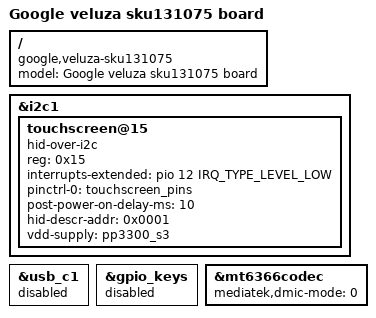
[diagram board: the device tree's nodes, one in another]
// SPDX-License-Identifier: (GPL-2.0 OR MIT)
/*
 * Copyright 2024 Google LLC
 */

/dts-v1/;
#include "mt8186-corsola-veluza.dtsi"

/ {
	model = "Google veluza sku131075 board";
	compatible = "google,veluza-sku131075", "google,veluza",
		     "google,corsola", "mediatek,mt8186";
};

&i2c1 {
	/delete-node/ touchscreen@10;
	touchscreen@15 {
		compatible = "hid-over-i2c";
		reg = <0x15>;
		interrupts-extended = <&pio 12 IRQ_TYPE_LEVEL_LOW>;
		pinctrl-names = "default";
		pinctrl-0 = <&touchscreen_pins>;
		post-power-on-delay-ms = <10>;
		hid-descr-addr = <0x0001>;
		vdd-supply = <&pp3300_s3>;
		status = "okay";
	};
};

&usb_c1 {
	status = "disabled";
};

&gpio_keys {
	status = "disabled";
};

&mt6366codec {
	mediatek,dmic-mode = <0>; /* two-wire */
};
